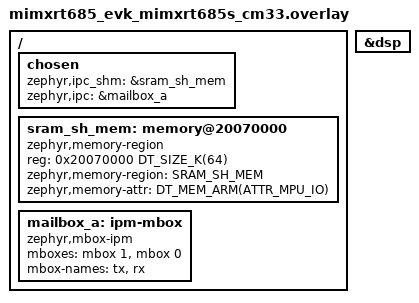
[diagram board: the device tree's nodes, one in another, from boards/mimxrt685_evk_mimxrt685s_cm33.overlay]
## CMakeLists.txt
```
#
# Copyright 2023-2026 NXP
#
# SPDX-License-Identifier: BSD-3-Clause
#

cmake_minimum_required(VERSION 3.20.0)

set(REMOTE_ZEPHYR_DIR ${CMAKE_CURRENT_BINARY_DIR}/../remote/zephyr)

find_package(Zephyr REQUIRED HINTS $ENV{ZEPHYR_BASE})
project(matrix_multiply_rpmsglite)

if(CONFIG_INCLUDE_REMOTE_DIR)
  target_include_directories(zephyr_interface
    INTERFACE ${REMOTE_ZEPHYR_DIR}/include/public)
endif()

enable_language(C CXX)

target_include_directories(app PRIVATE
    ${PROJECT_SOURCE_DIR}/
    ${PROJECT_SOURCE_DIR}/src
    ${PROJECT_SOURCE_DIR}/src/service
)

target_sources(app PRIVATE
    ${PROJECT_SOURCE_DIR}/src/main.cpp
    ${PROJECT_SOURCE_DIR}/src/erpc_error_handler.cpp

    # Generated shim code
    ${PROJECT_SOURCE_DIR}/src/service/c_erpc_matrix_multiply_client.cpp
    ${PROJECT_SOURCE_DIR}/src/service/erpc_matrix_multiply_client.cpp
    ${PROJECT_SOURCE_DIR}/src/service/erpc_matrix_multiply_interface.cpp
)

# Also include this directory into rpmsg_lite library because of project specific include rpsmg_config.h
target_include_directories(rpmsg_lite  PRIVATE ${CMAKE_CURRENT_SOURCE_DIR})
# Same for erpc library and erpc_config.h
target_include_directories(erpc PRIVATE ${CMAKE_CURRENT_SOURCE_DIR})

if (CONFIG_BOARD_MIMXRT685_EVK OR CONFIG_BOARD_MIMXRT700_EVK)
    include("${ZEPHYR_BASE}/samples/boards/nxp/adsp/rtxxx/common/dsp-load.cmake")
endif()
```

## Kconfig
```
#
# Copyright 2023-2026 NXP
#
# SPDX-License-Identifier: BSD-3-Clause
#

source "Kconfig.zephyr"

config INCLUDE_REMOTE_DIR
	bool "Include remote core header directory"
	help
	  Include remote build header files. Can be used if primary image
	  needs to be aware of size or base address of secondary image

config RPMSG_LITE_LINK_ID
	int "RPMSG-Lite Link ID"
	default 0
	help
	  Define here hardcoded to `0`. As all supported boards start with the link_id 0.
	  In case application specific change is required please refer to bellow.

	  Link ID used to define the rpmsg-lite instance, see rpmsg-lite/lib/include/<platform>/rpmsg_platform.h

config RPMSG_LITE_ENABLE_CACHE
	bool "Enable cache for RPMsg Lite"
	default n
	help
	  Enable cache support for RPMsg Lite communication.
```

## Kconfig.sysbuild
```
#
# Copyright 2023-2026 NXP
#
# SPDX-License-Identifier: BSD-3-Clause
#

source "share/sysbuild/Kconfig"

config RPMSG_LITE_REMOTE_BOARD
string
	default "lpcxpresso54114/lpc54114/m0" if $(BOARD) = "lpcxpresso54114"
	default "lpcxpresso55s69/lpc55s69/cpu1" if $(BOARD) = "lpcxpresso55s69"
	default "mps2/an521/cpu1" if $(BOARD) = "mps2"
	default "v2m_musca_b1/musca_b1/ns" if $(BOARD) = "v2m_musca_b1"
	default "mimxrt1170_evk/mimxrt1176/cm4" if $(BOARD) = "mimxrt1170_evk"
	default "mimxrt1160_evk/mimxrt1166/cm4" if $(BOARD) = "mimxrt1160_evk"
	default "mimxrt1170_evkb/mimxrt1176/cm4" if $(BOARD) = "mimxrt1170_evkb"
	default "mimxrt685_evk/mimxrt685s/hifi4" if $(BOARD) = "mimxrt685_evk"
	default "mimxrt700_evk/mimxrt798s/hifi4" if $(BOARD) = "mimxrt700_evk"
```

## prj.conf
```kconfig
# C++ Language Support
CONFIG_CPP=y
CONFIG_STD_CPP20=y
CONFIG_NEWLIB_LIBC=y
CONFIG_GLIBCXX_LIBCPP=y

# Compiler
CONFIG_MAIN_STACK_SIZE=4096
CONFIG_HEAP_MEM_POOL_SIZE=8192

# eRPC
CONFIG_ERPC=y
CONFIG_ERPC_TRANSPORT_RPMSG_LITE=y

# RPMSG Lite
CONFIG_IPM=y
CONFIG_EVENTS=y
CONFIG_PRINTK=y
CONFIG_RPMSGLITE=y
CONFIG_RPMSGLITE_QUEUE=y
CONFIG_RPMSGLITE_NS=y
CONFIG_TIMESLICE_SIZE=1
```

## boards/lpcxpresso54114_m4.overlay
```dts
/*
 * Copyright 2023-2024 NXP
 *
 * SPDX-License-Identifier: BSD-3-Clause
 */

/ {
	chosen {
		/*
		 * shared memory reserved for the inter-processor communication
		 */
		zephyr,ipc_shm = &sramx1;
		zephyr,ipc = &mailbox0;
	};

	sramx1:memory@4000000{
		compatible = "mmio-sram";
		reg = <0x4000000 0x8000>;
	};
};
```

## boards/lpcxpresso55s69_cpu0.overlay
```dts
/*
 * Copyright (c) 2019 Linaro Limited
 * Copyright 2023 NXP
 *
 * SPDX-License-Identifier: Apache-2.0
 */

/ {
	chosen {
		/*
		 * shared memory reserved for the inter-processor communication
		 */

		zephyr,ipc_shm = &sram4duplicate;
		zephyr,ipc = &mailbox0;
	};

	/* This is a duplication of sram4, workaround */
	sram4duplicate: memory@20040000 {
		compatible = "mmio-sram";
		reg = <0x20040000 DT_SIZE_K(16)>;
	};
};
```

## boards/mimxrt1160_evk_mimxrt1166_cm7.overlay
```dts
/*
 * Copyright 2023-2024 NXP
 *
 * SPDX-License-Identifier: BSD-3-Clause
 */

#include <zephyr/dt-bindings/memory-attr/memory-attr-arm.h>

/ {
	chosen {
		zephyr,ipc_shm = &ocram2_overlay;
	};

	/* OpenAMP fails with full 512K OCRAM2 memory region as shared memory.
	 * Define a subset of the OCRAM2 region for demo to use
	 * Note that shared memory must have specific MPU attributes set.
	 */
	ocram2_overlay: memory@202c0000{
		compatible = "zephyr,memory-region", "mmio-sram";
		reg = <0x202c0000 DT_SIZE_K(16)>;
		zephyr,memory-region="OCRAM2_OVERLAY";
		zephyr,memory-attr = <( DT_MEM_ARM(ATTR_MPU_IO) )>;
	};
};
```

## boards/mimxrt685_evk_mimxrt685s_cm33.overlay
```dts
/*
 * Copyright 2026 NXP
 *
 * SPDX-License-Identifier: Apache-2.0
 */

#include <zephyr/dt-bindings/ipc_service/static_vrings.h>
#include <zephyr/dt-bindings/memory-attr/memory-attr-arm.h>

#include <nxp/nxp_rt6xx_hifi4memsplit.dtsi>

&dsp {
	status = "okay";
};

/ {
	chosen {
		/*
		 * shared memory reserved for the inter-processor communication
		 */

		zephyr,ipc_shm = &sram_sh_mem;
		zephyr,ipc = &mailbox_a;
	};

	/* Define memory regions for IPC */
	sram_sh_mem: memory@20070000 {
		compatible = "zephyr,memory-region", "mmio-sram";
		reg = <0x20070000 DT_SIZE_K(64)>;
		zephyr,memory-region = "SRAM_SH_MEM";
		zephyr,memory-attr = <DT_MEM_ARM(ATTR_MPU_IO)>;
	};

	mailbox_a: ipm-mbox {
		compatible = "zephyr,mbox-ipm";
		mboxes = <&mbox 1>, <&mbox 0>;
		mbox-names = "tx", "rx";
	};
};
```

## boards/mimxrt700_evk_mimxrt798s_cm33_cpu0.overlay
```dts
/*
 * Copyright 2026 NXP
 *
 * SPDX-License-Identifier: Apache-2.0
 */

#include <zephyr/dt-bindings/ipc_service/static_vrings.h>
#include <zephyr/dt-bindings/memory-attr/memory-attr-arm.h>

&dsp {
	status = "okay";
};

/ {
	chosen {
		zephyr,ipc_shm = &sram_shared_mem_hifi4;
		zephyr,ipc = &mailbox_a_hifi4;
	};

	mailbox_a_hifi4: ipm-mbox-hifi4 {
		compatible = "zephyr,mbox-ipm";
		mboxes = <&mbox4_a 1>, <&mbox4_a 0>;
		mbox-names = "tx", "rx";
	};

	sram_shared_mem_hifi4: memory@20584000 {
		compatible = "zephyr,memory-region", "mmio-sram";
		reg = <0x20584000 DT_SIZE_K(16)>;
		zephyr,memory-region = "SRAM_SHARED_HIFI4";
		zephyr,memory-attr = <DT_MEM_ARM(ATTR_MPU_IO)>;
	};
};
```

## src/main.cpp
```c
/*
 * Copyright 2023-2026 NXP
 *
 * SPDX-License-Identifier: BSD-3-Clause
 */

#include <zephyr/kernel.h>

#include "rpmsg_lite.h"
#include "erpc_client_setup.h"
#include "erpc_matrix_multiply_common.h"
#include "c_erpc_matrix_multiply_client.h"
#include "erpc_error_handler.h"

#if defined(CONFIG_BOARD_MIMXRT685_EVK) || defined(CONFIG_BOARD_MIMXRT700_EVK)
#include "dsp.h"
#endif

/*******************************************************************************
 * Definitions
 ******************************************************************************/
#define ERPC_TRANSPORT_RPMSG_LITE_LINK_ID (CONFIG_RPMSG_LITE_LINK_ID)

extern char rpmsg_lite_base[];

#define MATRIX_ITEM_MAX_VALUE (50)
#define APP_ERPC_READY_EVENT_DATA (1U)

/*******************************************************************************
 * Variables
 ******************************************************************************/
extern bool g_erpc_error_occurred;

/*******************************************************************************
 * Prototypes
 ******************************************************************************/

/*******************************************************************************
 * Code
 ******************************************************************************/

/*!
 * @brief Fill matrices by random values
 */
static void fill_matrices(Matrix matrix1_ptr, Matrix matrix2_ptr)
{
    int32_t a, b;

    /* Fill both matrices by random values */
    for (a = 0; a < matrix_size; ++a)
    {
        for (b = 0; b < matrix_size; ++b)
        {
            matrix1_ptr[a][b] = rand() % MATRIX_ITEM_MAX_VALUE;
            matrix2_ptr[a][b] = rand() % MATRIX_ITEM_MAX_VALUE;
        }
    }
}

/*!
 * @brief Printing a matrix to the console
 */
static void print_matrix(Matrix matrix_ptr)
{
    int32_t a, b;

    for (a = 0; a < matrix_size; ++a)
    {
        for (b = 0; b < matrix_size; ++b)
        {
            printk("%4i ", matrix_ptr[a][b]);
        }
        printk("\r\n");
    }
}

int main(void)
{
    Matrix matrix1 = { 0 }, matrix2 = { 0 }, result_matrix = { 0 };

    /* RPMsg-Lite transport layer initialization */
    erpc_transport_t transport;
    erpc_client_t client;

#if defined(CONFIG_BOARD_MIMXRT685_EVK) || defined(CONFIG_BOARD_MIMXRT700_EVK)
    dsp_start();
    k_sleep(K_MSEC(500));
#endif

    transport = erpc_transport_rpmsg_lite_rtos_master_init(100, 101, ERPC_TRANSPORT_RPMSG_LITE_LINK_ID);

    /* MessageBufferFactory initialization */
    erpc_mbf_t message_buffer_factory;
    message_buffer_factory = erpc_mbf_rpmsg_init(transport);

    /* eRPC client side initialization */
    client = erpc_client_init(transport, message_buffer_factory);
    initMatrixMultiplyService_client(client);

    /* Set default error handler */
    erpc_client_set_error_handler(client, erpc_error_handler);

    /* Fill both matrices by random values */
    fill_matrices(matrix1, matrix2);

    /* Print both matrices on the console */
    printk("\r\nMatrix #1");
    printk("\r\n=========\r\n");
    print_matrix(matrix1);

    printk("\r\nMatrix #2");
    printk("\r\n=========\r\n");
    print_matrix(matrix2);

    for (;;)
    {
        printk("\r\neRPC request is sent to the server\r\n");

        erpcMatrixMultiply(matrix1, matrix2, result_matrix);

        /* Check if some error occurred in eRPC */
        if (g_erpc_error_occurred)
        {
            /* Exit program loop */
            break;
        }

        printk("\r\nResult matrix");
        printk("\r\n=============\r\n");
        print_matrix(result_matrix);

        env_sleep_msec(1000);

        /* Wait for 200ms to eliminate the button glitch */
        env_sleep_msec(200);

        /* Fill both matrices by random values */
        fill_matrices(matrix1, matrix2);

        /* Print both matrices on the console */
        printk("\r\nMatrix #1");
        printk("\r\n=========\r\n");
        print_matrix(matrix1);

        printk("\r\nMatrix #2");
        printk("\r\n=========\r\n");
        print_matrix(matrix2);
    }
    for (;;)
    {
    }
}
```
